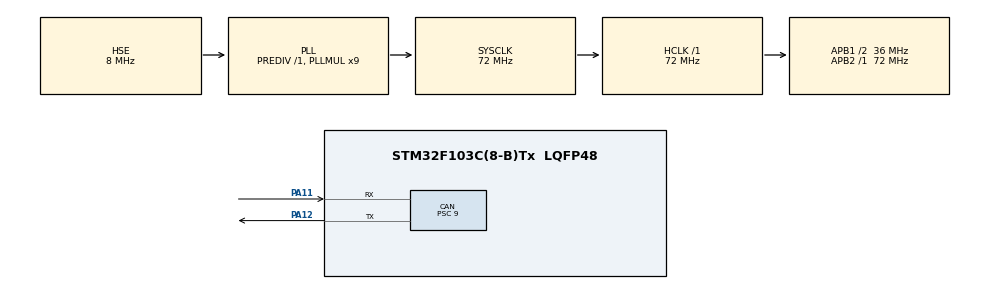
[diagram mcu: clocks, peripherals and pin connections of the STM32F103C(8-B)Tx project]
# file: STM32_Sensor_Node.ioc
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CAN.ABOM=ENABLE
CAN.BS1=CAN_BS1_6TQ
CAN.CalculateBaudRate=500000
CAN.CalculateTimeBit=2000
CAN.CalculateTimeQuantum=250.0
CAN.NART=ENABLE
CAN.Prescaler=9
Mcu.Family=STM32F1
Mcu.Name=STM32F103C(8-B)Tx
Mcu.Package=LQFP48
NVIC.PriorityGroup=NVIC_PRIORITYGROUP_4
PA11.Mode=CAN_Activate
PA11.Signal=CAN_RX
PA12.Mode=CAN_Activate
PA12.Signal=CAN_TX
PA13.Mode=Serial_Wire
PA13.Signal=SYS_JTMS-SWDIO
PA14.Mode=Serial_Wire
PA14.Signal=SYS_JTCK-SWCLK
PD0-OSC_IN.Mode=HSE-External-Oscillator
PD0-OSC_IN.Signal=RCC_OSC_IN
PD1-OSC_OUT.Mode=HSE-External-Oscillator
PD1-OSC_OUT.Signal=RCC_OSC_OUT
ProjectManager.HeapSize=0x200
ProjectManager.StackSize=0x400
ProjectManager.TargetToolchain=STM32CubeIDE
RCC.AHBFreq_Value=72000000
RCC.APB1CLKDivider=RCC_HCLK_DIV2
RCC.APB1Freq_Value=36000000
RCC.APB1TimFreq_Value=72000000
RCC.APB2Freq_Value=72000000
RCC.APB2TimFreq_Value=72000000
RCC.HCLKFreq_Value=72000000
RCC.PLLMUL=RCC_PLL_MUL9
RCC.PLLSourceVirtual=RCC_PLLSOURCE_HSE
RCC.SYSCLKFreq_VALUE=72000000
RCC.SYSCLKSource=RCC_SYSCLKSOURCE_PLLCLK
RCC.USBFreq_Value=72000000
board=custom

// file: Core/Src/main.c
/* USER CODE BEGIN Header */
/**
 ******************************************************************************
 * @file           : main.c
 * @brief          : Main program body
 ******************************************************************************
 * @attention
 *
 * Copyright (c) 2026 STMicroelectronics.
 * All rights reserved.
 *
 * This software is licensed under terms that can be found in the LICENSE file
 * in the root directory of this software component.
 * If no LICENSE file comes with this software, it is provided AS-IS.
 *
 ******************************************************************************
 */
/* USER CODE END Header */
#include "main.h"

/* USER CODE BEGIN Includes */
#include "usart1.h"
#include "adc1.h"
#include "dwt.h"
#include "i2c1.h"
#include "ds3231.h"
#include "dht11.h"
#include "mpu6050.h"
#include "timer2.h"
#include "timer3.h"
#include "can.h"
#include "tasks.h"
#include "button.h"
/* USER CODE END Includes */

/* USER CODE BEGIN PM */
#define ADC_READ_TICKS        1     // Read ADC every 100ms
#define DHT11_READ_TICKS      100    // Read DHT11 every 1 second
#define MPU_READ_TICKS        5      // Read MPU6050 every 50ms
#define SEND_TIME_TICKS       100    // Send time every 1 second
/* USER CODE END PM */

CAN_HandleTypeDef hcan;

void SystemClock_Config(void);
static void MX_GPIO_Init(void);
static void MX_CAN_Init(void);

int main(void)
{

  /* MCU Configuration--------------------------------------------------------*/

  /* Reset of all peripherals, Initializes the Flash interface and the Systick. */
  HAL_Init();

  /* Configure the system clock */
  SystemClock_Config();

  /* Initialize all configured peripherals */
  MX_GPIO_Init();
  MX_CAN_Init();
  /* USER CODE BEGIN 2 */

  DWT_Init();
  ADC1_Init();
  USART1_Init();
  TIMER2_Init();
  TIMER4_Init();
  I2C1_Init();

  // Initialize CAN application
  CAN_Init(&hcan);

  // Sensor read counters
  uint16_t adc_count = 0;
  uint16_t dht_count = 0;
  uint16_t mpu_count = 0;
  uint16_t timestamp_count = 0;

  // Initialize sensors
  DS3231_Init();
  MPU6050_Init();
  DHT11_Init();

  USART1_SendString("Sensor Node Ready\r\n");
  USART1_SendString("==================\r\n");

  Button_Init();

  TIMER3_SetupPeriod(10);  // 10ms period
  /* USER CODE END 2 */

  /* Infinite loop */
  while(1)
  {

    /* USER CODE BEGIN 3 */

    if(button_mode_changed)
    {
      button_mode_changed = 0;

      DisplayMode_t mode = Button_GetMode();

      // Send display mode via CAN
      if(CAN_SendDisplayMode((uint8_t) mode) == CAN_OK)
      {
        USART1_SendString("BTN: Mode ");
        USART1_SendNumber(mode);
        USART1_SendString(" sent via CAN\r\n");
      }
      else
      {
        USART1_SendString("CAN Error: Display Mode!\r\n");
      }
    }

    // ADC Potentiometer - Read & Send @ 10ms
    if(adc_count++ >= ADC_READ_TICKS)
    {
      // Start ADC conversion
      ADC1_StartConversion();

      // Wait for conversion complete
      uint32_t timeout = 100000;
      while(!adc_data_ready && --timeout);

      if(adc_data_ready)
      {
        uint16_t pot_value = adc_buffer;
        adc_data_ready = 0;

        // Store in global data structure
        sensor_data.potentiometer = pot_value;

        // Send IMMEDIATELY via CAN
        if(CAN_SendPotentiometer(pot_value) == CAN_OK)
        {
//          USART1_SendString("ADC: ");
//          USART1_SendNumber(pot_value);
//          USART1_SendString(" -> CAN OK\r\n");
        }
        else
        {
          USART1_SendString("CAN Error: Potentiometer!\r\n");
        }
      }
      else
      {
        USART1_SendString("ADC Timeout!\r\n");
      }

      adc_count = 0;
    }

    // DHT11 Temperature & Humidity - Read & Send second
    if(dht_count++ >= DHT11_READ_TICKS)
    {
      // Read DHT11 sensor
      Task_DHT11_Read();

      // Send via CAN using raw int/dec parts
      if(CAN_SendTempHumidity(dht11_humidity1, dht11_humidity2, dht11_temperature1, dht11_temperature2) == CAN_OK)
      {
        // Debug output
        USART1_SendString("DHT11: ");
        USART1_SendNumber(dht11_temperature1);
        USART1_SendChar('.');
        USART1_SendNumber(dht11_temperature2);
        USART1_SendString("C, ");
        USART1_SendNumber(dht11_humidity1);
        USART1_SendChar('.');
        USART1_SendNumber(dht11_humidity2);
        USART1_SendString("% -> CAN OK\r\n");
      }
      else
      {
        USART1_SendString("CAN Error: Temp/Humid!\r\n");
      }

      dht_count = 0;
    }

    // Read MPU6050 and send
    if(mpu_count++ >= MPU_READ_TICKS)
    {
      mpu_count = 0;
      Task_MPU6050_Send();  // Read and Send
    }

    if(timestamp_count++ >= SEND_TIME_TICKS)
    {
      timestamp_count = 0;
      CAN_SendTime();
    }

    TIMER3_WaitPeriod(); // 10ms heartbeat
  }
  /* USER CODE END 3 */
}

void SystemClock_Config(void)
{
  RCC_OscInitTypeDef RCC_OscInitStruct = { 0 };
  RCC_ClkInitTypeDef RCC_ClkInitStruct = { 0 };

  /** Initializes the RCC Oscillators according to the specified parameters
   * in the RCC_OscInitTypeDef structure.
   */
  RCC_OscInitStruct.OscillatorType = RCC_OSCILLATORTYPE_HSE;
  RCC_OscInitStruct.HSEState = RCC_HSE_ON;
  RCC_OscInitStruct.HSEPredivValue = RCC_HSE_PREDIV_DIV1;
  RCC_OscInitStruct.HSIState = RCC_HSI_ON;
  RCC_OscInitStruct.PLL.PLLState = RCC_PLL_ON;
  RCC_OscInitStruct.PLL.PLLSource = RCC_PLLSOURCE_HSE;
  RCC_OscInitStruct.PLL.PLLMUL = RCC_PLL_MUL9;
  if(HAL_RCC_OscConfig(&RCC_OscInitStruct) != HAL_OK)
  {
    Error_Handler();
  }

  /** Initializes the CPU, AHB and APB buses clocks
   */
  RCC_ClkInitStruct.ClockType = RCC_CLOCKTYPE_HCLK | RCC_CLOCKTYPE_SYSCLK | RCC_CLOCKTYPE_PCLK1 | RCC_CLOCKTYPE_PCLK2;
  RCC_ClkInitStruct.SYSCLKSource = RCC_SYSCLKSOURCE_PLLCLK;
  RCC_ClkInitStruct.AHBCLKDivider = RCC_SYSCLK_DIV1;
  RCC_ClkInitStruct.APB1CLKDivider = RCC_HCLK_DIV2;
  RCC_ClkInitStruct.APB2CLKDivider = RCC_HCLK_DIV1;

  if(HAL_RCC_ClockConfig(&RCC_ClkInitStruct, FLASH_LATENCY_2) != HAL_OK)
  {
    Error_Handler();
  }
}

static void MX_CAN_Init(void)
{

  hcan.Instance = CAN1;
  hcan.Init.Prescaler = 9;
  hcan.Init.Mode = CAN_MODE_NORMAL;
  hcan.Init.SyncJumpWidth = CAN_SJW_1TQ;
  hcan.Init.TimeSeg1 = CAN_BS1_6TQ;
  hcan.Init.TimeSeg2 = CAN_BS2_1TQ;
  hcan.Init.TimeTriggeredMode = DISABLE;
  hcan.Init.AutoBusOff = ENABLE;
  hcan.Init.AutoWakeUp = DISABLE;
  hcan.Init.AutoRetransmission = ENABLE;
  hcan.Init.ReceiveFifoLocked = DISABLE;
  hcan.Init.TransmitFifoPriority = DISABLE;
  if(HAL_CAN_Init(&hcan) != HAL_OK)
  {
    Error_Handler();
  }

}

static void MX_GPIO_Init(void)
{

  /* GPIO Ports Clock Enable */
  __HAL_RCC_GPIOD_CLK_ENABLE();
  __HAL_RCC_GPIOA_CLK_ENABLE();

}

void Error_Handler(void)
{
  __disable_irq();
  while(1)
  {
  }
}
